VERSION ""

NS_ :

BS_:

BU_: BCM BCW CAMERA CLU DATC EMS ESC IBOX LCA LVR PGS SCC SMK SNV TCU TPMS Vector__XXX XXX _4WD

CM_ "imported_from_opendbc.dbc";
CM_ "source: /home/trh/Packages/opendbc";
CM_ "logs: /home/trh/Packages/Ioniq5_CAN/CAN_logs";
CM_ "only messages validated against the logs are defined below";
CM_ "every BO_/SG_/VAL_/SG_MUL_VAL_ line is copied verbatim from the opendbc source file named in its comment, except where the source line is invalid and is noted next to the affected frame";
CM_ "Not imported, although the frame id matches the logs:";
CM_ "0x316  opendbc EMS11/EMS1 layout is wrong here: bytes 3-7 are constant, byte 2 is an alive counter, bytes 0-1 a checksum. The 'N = 304 rpm' reading is the counter.";
CM_ "0x251  opendbc MDPS12 layout is wrong here: CF_Mdps_Chksum2 (byte 3) is always 0x00 and bytes 4-7 are always 0; only the byte-2 counter lines up (+2 per frame).";
CM_ "0x180  checksum-proven (173/173) but opendbc has no correct 8-byte definition: the 8-byte entry is AMP_HU_PE_01 (audio amp) and CAM_0x180 is declared 32 bytes.";
CM_ "0x06F, 0x385  checksum-proven but no opendbc message definition exists.";
CM_ "Remaining frame-id matches are from the 2015-era platform files and were never payload-verified; importing them would add ~70 unverified messages. See dbc_log_overlap_report.txt section 3 for the full list.";

CM_ "0x185 CAM_0x185 from opendbc/dbc/hyundai_canfd_generated.dbc: T1 checksum-proven: 173/173 frames match hkg_can_fd_checksum()";
BO_ 389 CAM_0x185: 8 CAMERA
 SG_ CHECKSUM : 0|16@1+ (1,0) [0|65535] "" XXX
 SG_ COUNTER : 16|8@1+ (1,0) [0|255] "" XXX

CM_ "0x112 TCU12 from opendbc/dbc/hyundai_kia_generic.dbc: T2 CUR_GR decodes to P on all 4569 logged samples";
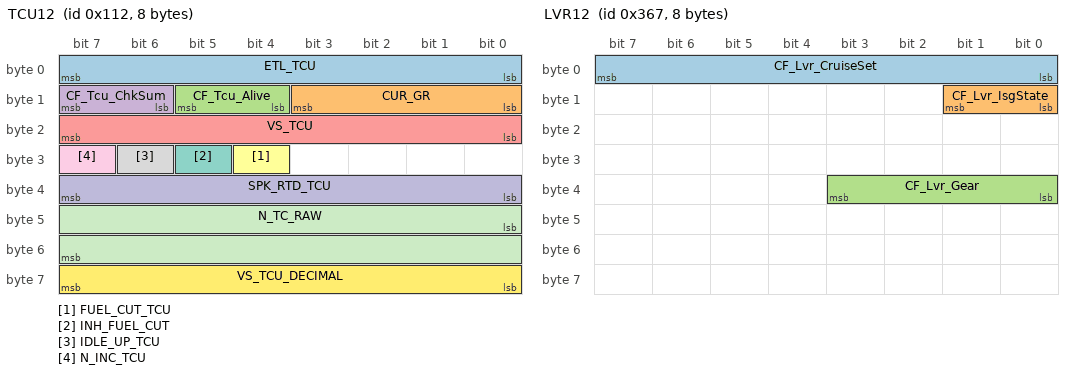
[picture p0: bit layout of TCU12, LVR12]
BO_ 274 TCU12: 8 TCU
 SG_ ETL_TCU : 0|8@1+ (2.0,0.0) [0.0|508.0] "Nm"  EMS,IBOX
 SG_ CUR_GR : 8|4@1+ (1.0,0.0) [0.0|15.0] ""  _4WD,EMS,ESC,IBOX,SCC,TPMS
 SG_ CF_Tcu_Alive : 12|2@1+ (1.0,0.0) [0.0|3.0] ""  EMS,ESC,IBOX,SCC
 SG_ CF_Tcu_ChkSum : 14|2@1+ (1.0,0.0) [0.0|3.0] ""  EMS,ESC,IBOX,SCC
 SG_ VS_TCU : 16|8@1+ (1.0,0.0) [0.0|254.0] "km/h"  BCM,CLU,DATC,EMS,IBOX,LCA,LVR,PGS,SMK,SNV
 SG_ FUEL_CUT_TCU : 28|1@1+ (1.0,0.0) [0.0|1.0] ""  EMS,IBOX
 SG_ INH_FUEL_CUT : 29|1@1+ (1.0,0.0) [0.0|1.0] ""  EMS,IBOX
 SG_ IDLE_UP_TCU : 30|1@1+ (1.0,0.0) [0.0|1.0] ""  EMS,IBOX
 SG_ N_INC_TCU : 31|1@1+ (1.0,0.0) [0.0|1.0] ""  EMS,IBOX
 SG_ SPK_RTD_TCU : 32|8@1+ (0.375,-23.625) [-15.0|15.0] ""  EMS,IBOX
 SG_ N_TC_RAW : 40|16@1+ (0.25,0.0) [0.0|16383.5] "rpm"  EMS,IBOX
 SG_ VS_TCU_DECIMAL : 56|8@1+ (0.0078125,0.0) [0.0|0.9921875] "km/h"  CLU,EMS,IBOX,LCA

VAL_ 274 CUR_GR 1 "D" 2 "D" 3 "D" 4 "D" 5 "D" 6 "D" 7 "D" 8 "D" 14 "R" 0 "P";

CM_ "0x367 LVR12 from opendbc/dbc/hyundai_kia_generic.dbc: T2 CF_Lvr_Gear decodes to P";
BO_ 871 LVR12: 8 LVR
 SG_ CF_Lvr_CruiseSet : 0|8@1+ (1.0,0.0) [0.0|255.0] "" CLU,TCU
 SG_ CF_Lvr_IsgState : 8|2@1+ (1.0,0.0) [0.0|3.0] "" CLU,TCU
 SG_ CF_Lvr_Gear : 32|4@1+ (1.0,0.0) [0.0|15.0] ""  CLU,TCU

VAL_ 871 CF_Lvr_IsgState 0 "enabled" 1 "activated" 2 "unknown" 3 "disabled";
VAL_ 871 CF_Lvr_Gear 12 "T" 5 "D" 8 "S" 6 "N" 7 "R" 0 "P";

CM_ "0x368 LVR11 from opendbc/dbc/hyundai_kia_generic.dbc: T2 CF_Lvr_Gear decodes to P";
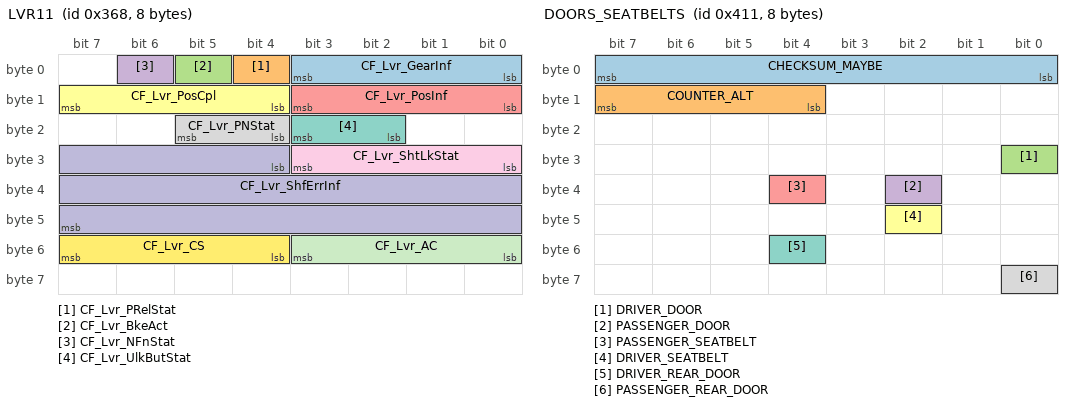
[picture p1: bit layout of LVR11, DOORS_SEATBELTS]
BO_ 872 LVR11: 8 LVR
 SG_ CF_Lvr_GearInf : 0|4@1+ (1.0,0.0) [0.0|15.0] ""  CLU,TCU
 SG_ CF_Lvr_PRelStat : 4|1@1+ (1.0,0.0) [0.0|1.0] ""  BCM,CLU,SMK,TCU
 SG_ CF_Lvr_BkeAct : 5|1@1+ (1.0,0.0) [0.0|1.0] ""  TCU
 SG_ CF_Lvr_NFnStat : 6|1@1+ (1.0,0.0) [0.0|1.0] ""  CLU
 SG_ CF_Lvr_PosInf : 8|4@1+ (1.0,0.0) [0.0|15.0] ""  TCU
 SG_ CF_Lvr_PosCpl : 12|4@1+ (1.0,0.0) [0.0|15.0] ""  TCU
 SG_ CF_Lvr_UlkButStat : 18|2@1+ (1.0,0.0) [0.0|3.0] ""  TCU
 SG_ CF_Lvr_PNStat : 20|2@1+ (1.0,0.0) [0.0|3.0] ""  CLU
 SG_ CF_Lvr_ShtLkStat : 24|4@1+ (1.0,0.0) [0.0|15.0] ""  TCU
 SG_ CF_Lvr_ShfErrInf : 28|20@1+ (1.0,0.0) [0.0|8191.0] ""  CLU,TCU
 SG_ CF_Lvr_AC : 48|4@1+ (1.0,0.0) [0.0|15.0] ""  TCU
 SG_ CF_Lvr_CS : 52|4@1+ (1.0,0.0) [0.0|15.0] ""  TCU

CM_ "0x394 TCS13 from opendbc/dbc/hyundai_kia_generic.dbc: T2 ACCEnable decodes to 'SCC ready'";
BO_ 916 TCS13: 8 ESC
 SG_ aBasis : 0|11@1+ (0.01,-10.23) [-10.23|10.24] "m/s^2"  EMS,SCC
 SG_ BrakeLight : 11|1@1+ (1.0,0.0) [0.0|1.0] ""  CLU,EMS,SCC
 SG_ DCEnable : 12|1@1+ (1.0,0.0) [0.0|1.0] ""  EMS,SCC
 SG_ AliveCounterTCS : 13|3@1+ (1.0,0.0) [0.0|7.0] ""  EMS,SCC
 SG_ Pre_TCS_CTL : 16|1@1+ (1.0,0.0) [0.0|1.0] ""  Vector__XXX
 SG_ EBA_ACK : 17|1@1+ (1.0,0.0) [0.0|1.0] ""  Vector__XXX
 SG_ FCA_ACK : 18|1@1+ (1.0,0.0) [0.0|1.0] ""  Vector__XXX
 SG_ DF_BF_STAT : 19|2@1+ (1.0,0.0) [0.0|3.0] ""  BCW
 SG_ SCCReqLim : 22|2@1+ (1.0,0.0) [0.0|3.0] ""  SCC
 SG_ TQI_SCC : 24|8@1+ (0.390625,0.0) [0.0|199.609375] "%"  Vector__XXX
 SG_ ACCEL_REF_ACC : 32|11@1+ (0.01,-10.23) [-10.23|10.24] "m/s^2"  EMS,SCC
 SG_ ACCEnable : 43|2@1+ (1.0,0.0) [0.0|3.0] ""  EMS,SCC
 SG_ DriverOverride : 45|2@1+ (1.0,0.0) [0.0|3.0] ""  EMS,SCC
 SG_ StandStill : 47|1@1+ (1.0,0.0) [0.0|1.0] ""  EMS,SCC
 SG_ CheckSum_TCS3 : 48|4@1+ (1.0,0.0) [0.0|15.0] ""  EMS,SCC
 SG_ ACC_EQUIP : 52|1@1+ (1.0,0.0) [0.0|1.0] ""  EMS,SCC
 SG_ PBRAKE_ACT : 53|1@1+ (1.0,0.0) [0.0|1.0] ""  EMS,SCC
 SG_ ACC_REQ : 54|1@1+ (1.0,0.0) [0.0|1.0] ""  EMS
 SG_ DriverBraking : 55|1@1+ (1.0,0.0) [0.0|1.0] ""  EMS,SCC
 SG_ CF_VSM_Coded : 56|1@1+ (1.0,0.0) [0.0|1.0] ""  SCC
 SG_ CF_VSM_Avail : 57|2@1+ (1.0,0.0) [0.0|3.0] ""  CLU,SCC
 SG_ CF_VSM_Handshake : 59|1@1+ (1.0,0.0) [0.0|1.0] ""  SCC
 SG_ CF_DriBkeStat : 60|1@1+ (1.0,0.0) [0.0|1.0] ""  SCC
 SG_ CF_VSM_ConfSwi : 61|2@1+ (1.0,0.0) [0.0|3.0] ""  SCC
 SG_ AEB_EQUIP : 63|1@1+ (1.0,0.0) [0.0|1.0] ""  SCC

VAL_ 916 ACCEnable 0 "SCC ready" 1 "SCC temp fault" 2 "SCC permanent fault" 3 "SCC permanent fault, communication issue";

CM_ "0x411 DOORS_SEATBELTS from opendbc/dbc/hyundai_canfd_generated.dbc: T2 DRIVER_DOOR reads Opened->Closed in M-CAN_panda_nothing_on.csv; VAL_ values all hit";
BO_ 1041 DOORS_SEATBELTS: 8 XXX
 SG_ CHECKSUM_MAYBE : 7|8@0+ (1,0) [0|65535] "" XXX
 SG_ COUNTER_ALT : 15|4@0+ (1,0) [0|15] "" XXX
 SG_ DRIVER_DOOR : 24|1@1+ (1,0) [0|1] "" XXX
 SG_ PASSENGER_DOOR : 34|1@0+ (1,0) [0|1] "" XXX
 SG_ PASSENGER_SEATBELT : 36|1@0+ (1,0) [0|1] "" XXX
 SG_ DRIVER_SEATBELT : 42|1@0+ (1,0) [0|1] "" XXX
 SG_ DRIVER_REAR_DOOR : 52|1@0+ (1,0) [0|1] "" XXX
 SG_ PASSENGER_REAR_DOOR : 56|1@0+ (1,0) [0|1] "" XXX

VAL_ 1041 DRIVER_DOOR 0 "Closed" 1 "Opened";
VAL_ 1041 PASSENGER_DOOR 0 "Closed" 1 "Opened";
VAL_ 1041 PASSENGER_SEATBELT 0 "Unlatched" 1 "Latched";
VAL_ 1041 DRIVER_SEATBELT 0 "Unlatched" 1 "Latched";
VAL_ 1041 DRIVER_REAR_DOOR 0 "Closed" 1 "Opened";
VAL_ 1041 PASSENGER_REAR_DOOR 0 "Closed" 1 "Opened";

CM_ "0x413 BLINKERS from opendbc/dbc/hyundai_canfd_generated.dbc: T2 LEFT_STALK=1 with LEFT_LAMP blinking ~0.35s in the driving log; RIGHT_STALK=0";
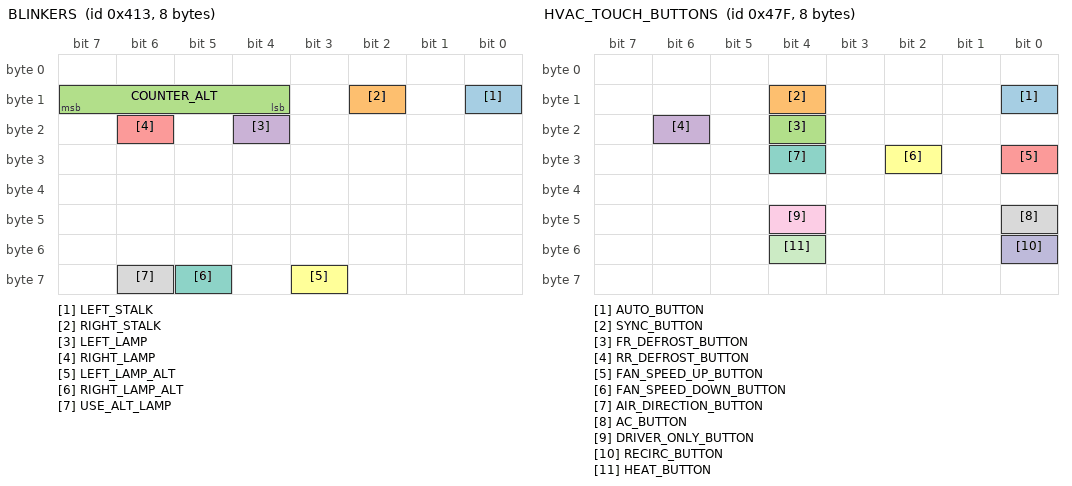
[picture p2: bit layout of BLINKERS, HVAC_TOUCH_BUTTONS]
BO_ 1043 BLINKERS: 8 XXX
 SG_ LEFT_STALK : 8|1@0+ (1,0) [0|1] "" XXX
 SG_ RIGHT_STALK : 10|1@0+ (1,0) [0|1] "" XXX
 SG_ COUNTER_ALT : 15|4@0+ (1,0) [0|15] "" XXX
 SG_ LEFT_LAMP : 20|1@0+ (1,0) [0|1] "" XXX
 SG_ RIGHT_LAMP : 22|1@0+ (1,0) [0|1] "" XXX
 SG_ LEFT_LAMP_ALT : 59|1@0+ (1,0) [0|1] "" XXX
 SG_ RIGHT_LAMP_ALT : 61|1@0+ (1,0) [0|1] "" XXX
 SG_ USE_ALT_LAMP : 62|1@0+ (1,0) [0|1] "" XXX

CM_ "0x47F HVAC_TOUCH_BUTTONS from opendbc/dbc/hyundai_canfd_generated.dbc: T2 AUTO_BUTTON toggles 0->1->0 in M-CAN_climate_auto_press_3x_2x_6-24.csv, stays 0 in climate_press";
BO_ 1151 HVAC_TOUCH_BUTTONS: 8 XXX
 SG_ AUTO_BUTTON : 8|1@0+ (1,0) [0|1] "" XXX
 SG_ SYNC_BUTTON : 12|1@0+ (1,0) [0|1] "" XXX
 SG_ FR_DEFROST_BUTTON : 20|1@0+ (1,0) [0|1] "" XXX
 SG_ RR_DEFROST_BUTTON : 22|1@0+ (1,0) [0|1] "" XXX
 SG_ FAN_SPEED_UP_BUTTON : 24|1@0+ (1,0) [0|1] "" XXX
 SG_ FAN_SPEED_DOWN_BUTTON : 26|1@0+ (1,0) [0|1] "" XXX
 SG_ AIR_DIRECTION_BUTTON : 28|1@0+ (1,0) [0|1] "" XXX
 SG_ AC_BUTTON : 40|1@0+ (1,0) [0|1] "" XXX
 SG_ DRIVER_ONLY_BUTTON : 44|1@0+ (1,0) [0|1] "" XXX
 SG_ RECIRC_BUTTON : 48|1@0+ (1,0) [0|1] "" XXX
 SG_ HEAT_BUTTON : 52|1@0+ (1,0) [0|1] "" XXX

CM_ "0x485 LFAHDA_MFC from opendbc/dbc/hyundai_palisade_2023_generated.dbc: T2 HDA_Icon_State='green_hda', LFA_Icon_State in {white_wheel,green_wheel}";
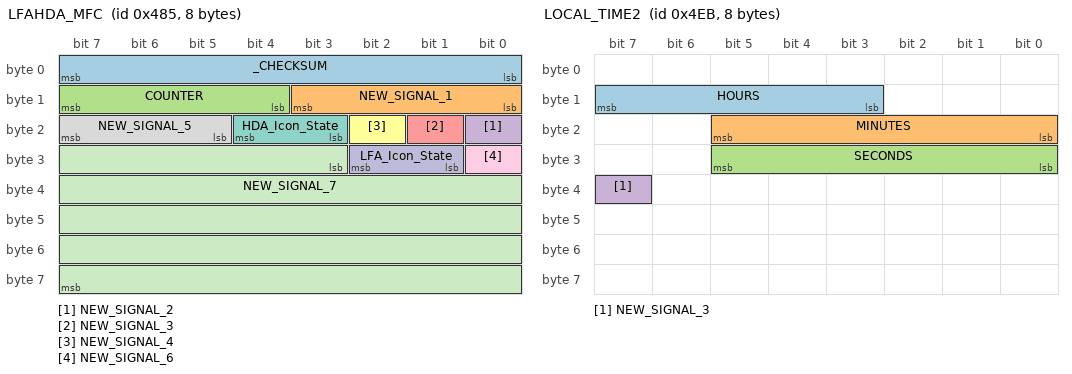
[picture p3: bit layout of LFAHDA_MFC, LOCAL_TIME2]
BO_ 1157 LFAHDA_MFC: 8 XXX
 SG_ _CHECKSUM : 0|8@1+ (1,0) [0|0] "" XXX
 SG_ NEW_SIGNAL_1 : 8|4@1+ (1,0) [0|0] "" XXX
 SG_ COUNTER : 12|4@1+ (1,0) [0|0] "" XXX
 SG_ NEW_SIGNAL_2 : 16|1@0+ (1,0) [0|0] "" XXX
 SG_ NEW_SIGNAL_3 : 17|1@0+ (1,0) [0|0] "" XXX
 SG_ NEW_SIGNAL_4 : 18|1@0+ (1,0) [0|0] "" XXX
 SG_ HDA_Icon_State : 19|2@1+ (1,0) [0|0] "" XXX
 SG_ NEW_SIGNAL_5 : 21|3@1+ (1,0) [0|0] "" XXX
 SG_ NEW_SIGNAL_6 : 24|1@0+ (1,0) [0|0] "" XXX
 SG_ LFA_Icon_State : 25|2@1+ (1,0) [0|0] "" XXX
 SG_ NEW_SIGNAL_7 : 27|37@1+ (1,0) [0|0] "" XXX

VAL_ 1157 HDA_Icon_State 0 "no_hda" 1 "white_hda" 2 "green_hda";
VAL_ 1157 LFA_Icon_State 0 "no_wheel" 1 "white_wheel" 2 "green_wheel" 3 "green_wheel_blink";

CM_ "VAL_ 1157 LFA_SysWarning and VAL_ 1157 HDA_SysWarning are deliberately omitted: opendbc/dbc/hyundai_palisade_2023_generated.dbc declares those choice tables under BO_ 1157 but never defines LFA_SysWarning or HDA_SysWarning as signals in that frame (upstream defect), and cantools rejects VAL_ entries that no SG_ claims. Their decoded meanings if the signals are ever located: LFA_SysWarning 0=no_message 1=switching_to_hda 2=switching_to_scc 3=lfa_error 4=check_hda 5=keep_hands_on_wheel_orange 6=keep_hands_on_wheel_red; HDA_SysWarning 0=no_message 1=driving_convenience_systems_cancelled 2=highway_drive_assist_system_cancelled.";

CM_ "0x4D8 CLUSTER_INFO from opendbc/dbc/hyundai_canfd_generated.dbc: T2 DISTANCE_UNIT decodes to Miles";
BO_ 1240 CLUSTER_INFO: 8 XXX
 SG_ DISTANCE_UNIT : 0|1@1+ (1,0) [0|1] "" XXX

VAL_ 1240 DISTANCE_UNIT 1 "Miles" 0 "Kilometers";

CM_ "0x4EB LOCAL_TIME2 from opendbc/dbc/hyundai_canfd_generated.dbc: T2 HOURS/MINUTES/SECONDS advance like a clock";
BO_ 1259 LOCAL_TIME2: 8 XXX
 SG_ HOURS : 15|5@0+ (1,0) [0|31] "" XXX
 SG_ MINUTES : 21|6@0+ (1,0) [0|63] "" XXX
 SG_ SECONDS : 24|6@1+ (1,0) [0|63] "" XXX
 SG_ NEW_SIGNAL_3 : 39|1@0+ (1,0) [0|1] "" XXX
